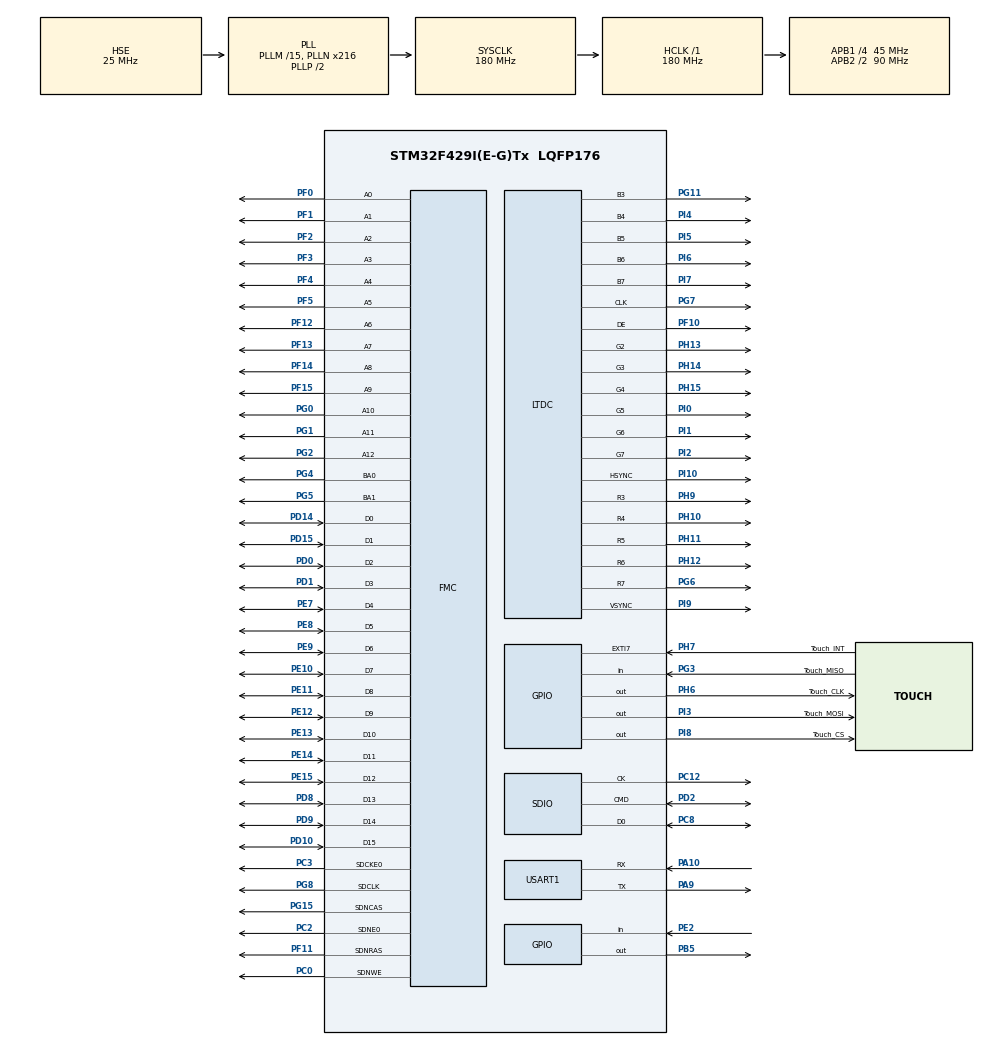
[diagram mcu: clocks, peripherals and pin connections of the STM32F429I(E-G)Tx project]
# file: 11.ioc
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DMA2D.ColorMode=DMA2D_OUTPUT_RGB565
FATFS.BSP.number=1
FATFS0.BSP.STBoard=false
FATFS0.BSP.api=Unknown
FATFS0.BSP.i2caddr=0
FATFS0.BSP.instance=PE2
FATFS0.BSP.ip=GPIO
FATFS0.BSP.mode=Input
FATFS0.BSP.name=Detect_SDIO
FATFS0.BSP.solution=PE2
FMC.CASLatency1=FMC_SDRAM_CAS_LATENCY_3
FMC.ColumnBitsNumber1=FMC_SDRAM_COLUMN_BITS_NUM_9
FMC.ExitSelfRefreshDelay1=7
FMC.LoadToActiveDelay1=2
FMC.RCDDelay1=2
FMC.RPDelay1=2
FMC.ReadBurst1=FMC_SDRAM_RBURST_ENABLE
FMC.RowCycleDelay1=6
FMC.SDClockPeriod1=FMC_SDRAM_CLOCK_PERIOD_2
FMC.SelfRefreshTime1=6
FMC.WriteRecoveryTime1=5
LTDC.ActiveW=800
LTDC.Alpha_L0=255
LTDC.Blue_L0=0
LTDC.HFP=210
LTDC.ImageHeight_L0=480
LTDC.ImageWidth_L0=800
LTDC.Layers=0
LTDC.PixelFormat_L0=LTDC_PIXEL_FORMAT_RGB565
LTDC.Red=0
LTDC.Red_L0=250
LTDC.VFP=22
LTDC.WindowX0_L0=0
LTDC.WindowX1_L0=800
LTDC.WindowY0_L0=0
LTDC.WindowY1_L0=480
Mcu.Family=STM32F4
Mcu.Name=STM32F429I(E-G)Tx
Mcu.Package=LQFP176
NVIC.DMA2D_IRQn=true\:0\:0\:false\:false\:true\:true\:true
NVIC.EXTI9_5_IRQn=true\:0\:0\:false\:false\:true\:true\:true
NVIC.LTDC_ER_IRQn=true\:0\:0\:false\:false\:true\:true\:true
NVIC.LTDC_IRQn=true\:0\:0\:false\:false\:true\:true\:true
NVIC.PriorityGroup=NVIC_PRIORITYGROUP_4
PA10.Mode=Asynchronous
PA10.Signal=USART1_RX
PA13.Mode=Serial_Wire
PA13.Signal=SYS_JTMS-SWDIO
PA14.Mode=Serial_Wire
PA14.Signal=SYS_JTCK-SWCLK
PA9.Mode=Asynchronous
PA9.Signal=USART1_TX
PB5.Signal=GPIO_Output
PC0.Signal=FMC_SDNWE
PC12.Mode=SD_1_bit
PC12.Signal=SDIO_CK
PC2.Mode=SdramChipSelect1_1
PC2.Signal=FMC_SDNE0
PC3.Mode=SdramChipSelect1_1
PC3.Signal=FMC_SDCKE0
PC8.Mode=SD_1_bit
PC8.Signal=SDIO_D0
PD0.Signal=FMC_D2_DA2
PD1.Signal=FMC_D3_DA3
PD10.Signal=FMC_D15_DA15
PD14.Signal=FMC_D0_DA0
PD15.Signal=FMC_D1_DA1
PD2.Mode=SD_1_bit
PD2.Signal=SDIO_CMD
PD8.Signal=FMC_D13_DA13
PD9.Signal=FMC_D14_DA14
PE10.Signal=FMC_D7_DA7
PE11.Signal=FMC_D8_DA8
PE12.Signal=FMC_D9_DA9
PE13.Signal=FMC_D10_DA10
PE14.Signal=FMC_D11_DA11
PE15.Signal=FMC_D12_DA12
PE2.Signal=GPIO_Input
PE7.Signal=FMC_D4_DA4
PE8.Signal=FMC_D5_DA5
PE9.Signal=FMC_D6_DA6
PF0.Signal=FMC_A0
PF1.Signal=FMC_A1
PF10.Mode=RGB565
PF10.Signal=LTDC_DE
PF11.Signal=FMC_SDNRAS
PF12.Signal=FMC_A6
PF13.Signal=FMC_A7
PF14.Signal=FMC_A8
PF15.Signal=FMC_A9
PF2.Signal=FMC_A2
PF3.Signal=FMC_A3
PF4.Signal=FMC_A4
PF5.Signal=FMC_A5
PG0.Signal=FMC_A10
PG1.Signal=FMC_A11
PG11.Mode=RGB565
PG11.Signal=LTDC_B3
PG15.Signal=FMC_SDNCAS
PG2.Signal=FMC_A12
PG3.GPIO_Label=Touch_MISO
PG3.Signal=GPIO_Input
PG4.Signal=FMC_A14_BA0
PG5.Signal=FMC_A15_BA1
PG6.Mode=RGB565
PG6.Signal=LTDC_R7
PG7.Mode=RGB565
PG7.Signal=LTDC_CLK
PG8.Signal=FMC_SDCLK
PH0/OSC_IN.Mode=HSE-External-Oscillator
PH0/OSC_IN.Signal=RCC_OSC_IN
PH1/OSC_OUT.Mode=HSE-External-Oscillator
PH1/OSC_OUT.Signal=RCC_OSC_OUT
PH10.Mode=RGB565
PH10.Signal=LTDC_R4
PH11.Mode=RGB565
PH11.Signal=LTDC_R5
PH12.Mode=RGB565
PH12.Signal=LTDC_R6
PH13.Mode=RGB565
PH13.Signal=LTDC_G2
PH14.Mode=RGB565
PH14.Signal=LTDC_G3
PH15.Mode=RGB565
PH15.Signal=LTDC_G4
PH6.GPIO_Label=Touch_CLK
PH6.Signal=GPIO_Output
PH7.GPIO_Label=Touch_INT
PH7.GPIO_ModeDefaultEXTI=GPIO_MODE_IT_FALLING
PH7.GPIO_PuPd=GPIO_PULLUP
PH7.Signal=GPXTI7
PH9.Mode=RGB565
PH9.Signal=LTDC_R3
PI0.Mode=RGB565
PI0.Signal=LTDC_G5
PI1.Mode=RGB565
PI1.Signal=LTDC_G6
PI10.Mode=RGB565
PI10.Signal=LTDC_HSYNC
PI2.Mode=RGB565
PI2.Signal=LTDC_G7
PI3.GPIO_Label=Touch_MOSI
PI3.Signal=GPIO_Output
PI4.Mode=RGB565
PI4.Signal=LTDC_B4
PI5.Mode=RGB565
PI5.Signal=LTDC_B5
PI6.Mode=RGB565
PI6.Signal=LTDC_B6
PI7.Mode=RGB565
PI7.Signal=LTDC_B7
PI8.GPIO_Label=Touch_CS
PI8.Signal=GPIO_Output
PI9.Mode=RGB565
PI9.Signal=LTDC_VSYNC
ProjectManager.HeapSize=0x2000
ProjectManager.StackSize=0x4000
ProjectManager.TargetToolchain=STM32CubeIDE
RCC.48MHZClocksFreq_Value=45000000
RCC.AHBFreq_Value=180000000
RCC.APB1CLKDivider=RCC_HCLK_DIV4
RCC.APB1Freq_Value=45000000
RCC.APB1TimFreq_Value=90000000
RCC.APB2CLKDivider=RCC_HCLK_DIV2
RCC.APB2Freq_Value=90000000
RCC.APB2TimFreq_Value=180000000
RCC.CortexFreq_Value=180000000
RCC.HCLKFreq_Value=180000000
RCC.HSE_VALUE=25000000
RCC.HSI_VALUE=16000000
RCC.LSE_VALUE=32768
RCC.PLLM=15
RCC.PLLN=216
RCC.PLLQ=8
RCC.PLLSAIN=60
RCC.PLLSourceVirtual=RCC_PLLSOURCE_HSE
RCC.SYSCLKFreq_VALUE=180000000
RCC.SYSCLKSource=RCC_SYSCLKSOURCE_PLLCLK
RCC.VCOOutputFreq_Value=360000000
SH.FMC_A0.0=FMC_A0,13b-sda1
SH.FMC_A1.0=FMC_A1,13b-sda1
SH.FMC_A10.0=FMC_A10,13b-sda1
SH.FMC_A11.0=FMC_A11,13b-sda1
SH.FMC_A12.0=FMC_A12,13b-sda1
SH.FMC_A14_BA0.0=FMC_BA0,FourSdramBanks1
SH.FMC_A15_BA1.0=FMC_BA1,FourSdramBanks1
SH.FMC_A2.0=FMC_A2,13b-sda1
SH.FMC_A3.0=FMC_A3,13b-sda1
SH.FMC_A4.0=FMC_A4,13b-sda1
SH.FMC_A5.0=FMC_A5,13b-sda1
SH.FMC_A6.0=FMC_A6,13b-sda1
SH.FMC_A7.0=FMC_A7,13b-sda1
SH.FMC_A8.0=FMC_A8,13b-sda1
SH.FMC_A9.0=FMC_A9,13b-sda1
SH.FMC_D0_DA0.0=FMC_D0,sd-16b-d1
SH.FMC_D10_DA10.0=FMC_D10,sd-16b-d1
SH.FMC_D11_DA11.0=FMC_D11,sd-16b-d1
SH.FMC_D12_DA12.0=FMC_D12,sd-16b-d1
SH.FMC_D13_DA13.0=FMC_D13,sd-16b-d1
SH.FMC_D14_DA14.0=FMC_D14,sd-16b-d1
SH.FMC_D15_DA15.0=FMC_D15,sd-16b-d1
SH.FMC_D1_DA1.0=FMC_D1,sd-16b-d1
SH.FMC_D2_DA2.0=FMC_D2,sd-16b-d1
SH.FMC_D3_DA3.0=FMC_D3,sd-16b-d1
SH.FMC_D4_DA4.0=FMC_D4,sd-16b-d1
SH.FMC_D5_DA5.0=FMC_D5,sd-16b-d1
SH.FMC_D6_DA6.0=FMC_D6,sd-16b-d1
SH.FMC_D7_DA7.0=FMC_D7,sd-16b-d1
SH.FMC_D8_DA8.0=FMC_D8,sd-16b-d1
SH.FMC_D9_DA9.0=FMC_D9,sd-16b-d1
SH.FMC_SDCLK.0=FMC_SDCLK,13b-sda1
SH.FMC_SDNCAS.0=FMC_SDNCAS,13b-sda1
SH.FMC_SDNRAS.0=FMC_SDNRAS,13b-sda1
SH.FMC_SDNWE.0=FMC_SDNWE,13b-sda1
STMicroelectronics.X-CUBE-TOUCHGFX.4.13.0.ApplicationCcGraphicsJjApplication=TouchGFXOoGenerator
STMicroelectronics.X-CUBE-TOUCHGFX.4.13.0.tgfx_address1=0XC0000000
STMicroelectronics.X-CUBE-TOUCHGFX.4.13.0.tgfx_buffering_strategy=Single
STMicroelectronics.X-CUBE-TOUCHGFX.4.13.0.tgfx_custom_height=480
STMicroelectronics.X-CUBE-TOUCHGFX.4.13.0.tgfx_display_interface=disp_ltdc
STMicroelectronics.X-CUBE-TOUCHGFX.4.13.0.tgfx_hardware_accelerator=dma_2d
STMicroelectronics.X-CUBE-TOUCHGFX.4.13.0.tgfx_location=By Address
STMicroelectronics.X-CUBE-TOUCHGFX.4.13.0.tgfx_ltdc_height=480
STMicroelectronics.X-CUBE-TOUCHGFX.4.13.0.tgfx_ltdc_width=800
STMicroelectronics.X-CUBE-TOUCHGFX.4.13.0.tgfx_vsync=vsync_ltdc
USART1.VirtualMode=VM_ASYNC
VP_CRC_VS_CRC.Mode=CRC_Activate
VP_DMA2D_VS_DMA2D.Mode=DMA2D_Activate
VP_FATFS_VS_SDIO.Mode=SDIO
VP_STMicroelectronics.X-CUBE-TOUCHGFX_VS_GraphicsJjApplication_4.13.0.Mode=GraphicsJjApplication
board=custom

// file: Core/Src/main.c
/* USER CODE BEGIN Header */
/**
  ******************************************************************************
  * @file           : main.c
  * @brief          : Main program body
  ******************************************************************************
  * @attention
  *
  * <h2><center>&copy; Copyright (c) 2020 STMicroelectronics.
  * All rights reserved.</center></h2>
  *
  * This software component is licensed by ST under BSD 3-Clause license,
  * the "License"; You may not use this file except in compliance with the
  * License. You may obtain a copy of the License at:
  *                        opensource.org/licenses/BSD-3-Clause
  *
  ******************************************************************************
  */
/* USER CODE END Header */

#include "main.h"
#include "crc.h"
#include "dma2d.h"
#include "fatfs.h"
#include "ltdc.h"
#include "sdio.h"
#include "usart.h"
#include "gpio.h"
#include "fmc.h"
#include "app_touchgfx.h"

/* USER CODE BEGIN Includes */
//#include "XPTC.h"
#include "stdbool.h"
bool data=false;
bool toggle;
/* USER CODE END Includes */

void SystemClock_Config(void);

int main(void)
{
  /* USER CODE BEGIN 1 */
	toggle = false;

  /* USER CODE END 1 */

  /* MCU Configuration--------------------------------------------------------*/

  /* Reset of all peripherals, Initializes the Flash interface and the Systick. */
  HAL_Init();

  /* Configure the system clock */
  SystemClock_Config();

  /* Initialize all configured peripherals */
  MX_GPIO_Init();
  MX_FMC_Init();
  FMC_SDRAM_CommandTypeDef command;
////Enable The clock
HAL_Delay(100);
command.CommandMode = FMC_SDRAM_CMD_CLK_ENABLE;
command.CommandTarget = FMC_SDRAM_CMD_TARGET_BANK1;
command.AutoRefreshNumber= 2;
command.ModeRegisterDefinition=0;
HAL_SDRAM_SendCommand(&hsdram1, &command, 5000);
HAL_Delay(100);
////Precharge SDRAM
command.CommandMode = FMC_SDRAM_CMD_PALL;
command.CommandTarget = FMC_SDRAM_CMD_TARGET_BANK1;
command.AutoRefreshNumber= 4;
command.ModeRegisterDefinition=0;
HAL_SDRAM_SendCommand(&hsdram1, &command, 5000);
HAL_Delay(100);
////Precharge SDRAM
command.CommandMode = FMC_SDRAM_CMD_AUTOREFRESH_MODE;
command.CommandTarget = FMC_SDRAM_CMD_TARGET_BANK1;
command.AutoRefreshNumber= 8;
command.ModeRegisterDefinition=0;
HAL_SDRAM_SendCommand(&hsdram1, &command, 5000);
HAL_Delay(100);
///
command.CommandMode = FMC_SDRAM_CMD_LOAD_MODE;
    command.CommandTarget = FMC_SDRAM_CMD_TARGET_BANK1;
    command.AutoRefreshNumber= 4;
    command.ModeRegisterDefinition=0x130;
    HAL_SDRAM_SendCommand(&hsdram1, &command, 5000);
    HAL_Delay(100);
    ///
HAL_SDRAM_WriteProtection_Disable(&hsdram1);
HAL_Delay(100);
  MX_USART1_UART_Init();
  MX_CRC_Init();
  MX_LTDC_Init();
  MX_SDIO_SD_Init();
  MX_FATFS_Init();
  MX_DMA2D_Init();
  MX_TouchGFX_Init();
  /* USER CODE BEGIN 2 */
  /*
	////////////////////////////////////////////////////////////////////////////SDRAM CONFIG
	   FMC_SDRAM_CommandTypeDef command;
     ////Enable The clock
     HAL_Delay(100);
     command.CommandMode = FMC_SDRAM_CMD_CLK_ENABLE;
     command.CommandTarget = FMC_SDRAM_CMD_TARGET_BANK1;
     command.AutoRefreshNumber= 2;
     command.ModeRegisterDefinition=0;
     HAL_SDRAM_SendCommand(&hsdram1, &command, 5000);
     HAL_Delay(100);
     ////Precharge SDRAM
     command.CommandMode = FMC_SDRAM_CMD_PALL;
     command.CommandTarget = FMC_SDRAM_CMD_TARGET_BANK1;
     command.AutoRefreshNumber= 4;
     command.ModeRegisterDefinition=0;
     HAL_SDRAM_SendCommand(&hsdram1, &command, 5000);
     HAL_Delay(100);
     ////Precharge SDRAM
     command.CommandMode = FMC_SDRAM_CMD_AUTOREFRESH_MODE;
     command.CommandTarget = FMC_SDRAM_CMD_TARGET_BANK1;
     command.AutoRefreshNumber= 8;
     command.ModeRegisterDefinition=0;
     HAL_SDRAM_SendCommand(&hsdram1, &command, 5000);
     HAL_Delay(100);
     ///
     command.CommandMode = FMC_SDRAM_CMD_LOAD_MODE;
         command.CommandTarget = FMC_SDRAM_CMD_TARGET_BANK1;
         command.AutoRefreshNumber= 4;
         command.ModeRegisterDefinition=0x130;
         HAL_SDRAM_SendCommand(&hsdram1, &command, 5000);
         HAL_Delay(100);
         ///
     HAL_SDRAM_WriteProtection_Disable(&hsdram1);
     HAL_Delay(100);
	 */
     ///////////////////////////////////////////////////////////////////////////TURN LCD ON
       HAL_GPIO_WritePin(GPIOB, GPIO_PIN_5, GPIO_PIN_SET);
        HAL_UART_Transmit(&huart1, (uint8_t*)"START\n", 6, 5000);
        //XPT_init();
       ///////////////////////////////////////////////////////////////
  /* USER CODE END 2 */

  /* Infinite loop */
  /* USER CODE BEGIN WHILE */
        FIL pngfile;
        //char pngpath[]="\pic.png\0";
        char pngbuffer[6000];
        UINT pngcounter;

  while (1)
  {

  MX_TouchGFX_Process();
  }
}

void SystemClock_Config(void)
{
  RCC_OscInitTypeDef RCC_OscInitStruct = {0};
  RCC_ClkInitTypeDef RCC_ClkInitStruct = {0};
  RCC_PeriphCLKInitTypeDef PeriphClkInitStruct = {0};

  /** Configure the main internal regulator output voltage
  */
  __HAL_RCC_PWR_CLK_ENABLE();
  __HAL_PWR_VOLTAGESCALING_CONFIG(PWR_REGULATOR_VOLTAGE_SCALE1);
  /** Initializes the CPU, AHB and APB busses clocks
  */
  RCC_OscInitStruct.OscillatorType = RCC_OSCILLATORTYPE_HSE;
  RCC_OscInitStruct.HSEState = RCC_HSE_ON;
  RCC_OscInitStruct.PLL.PLLState = RCC_PLL_ON;
  RCC_OscInitStruct.PLL.PLLSource = RCC_PLLSOURCE_HSE;
  RCC_OscInitStruct.PLL.PLLM = 15;
  RCC_OscInitStruct.PLL.PLLN = 216;
  RCC_OscInitStruct.PLL.PLLP = RCC_PLLP_DIV2;
  RCC_OscInitStruct.PLL.PLLQ = 8;
  if (HAL_RCC_OscConfig(&RCC_OscInitStruct) != HAL_OK)
  {
    Error_Handler();
  }
  /** Activate the Over-Drive mode
  */
  if (HAL_PWREx_EnableOverDrive() != HAL_OK)
  {
    Error_Handler();
  }
  /** Initializes the CPU, AHB and APB busses clocks
  */
  RCC_ClkInitStruct.ClockType = RCC_CLOCKTYPE_HCLK|RCC_CLOCKTYPE_SYSCLK
                              |RCC_CLOCKTYPE_PCLK1|RCC_CLOCKTYPE_PCLK2;
  RCC_ClkInitStruct.SYSCLKSource = RCC_SYSCLKSOURCE_PLLCLK;
  RCC_ClkInitStruct.AHBCLKDivider = RCC_SYSCLK_DIV1;
  RCC_ClkInitStruct.APB1CLKDivider = RCC_HCLK_DIV4;
  RCC_ClkInitStruct.APB2CLKDivider = RCC_HCLK_DIV2;

  if (HAL_RCC_ClockConfig(&RCC_ClkInitStruct, FLASH_LATENCY_5) != HAL_OK)
  {
    Error_Handler();
  }
  PeriphClkInitStruct.PeriphClockSelection = RCC_PERIPHCLK_LTDC;
  PeriphClkInitStruct.PLLSAI.PLLSAIN = 60;
  PeriphClkInitStruct.PLLSAI.PLLSAIR = 2;
  PeriphClkInitStruct.PLLSAIDivR = RCC_PLLSAIDIVR_2;
  if (HAL_RCCEx_PeriphCLKConfig(&PeriphClkInitStruct) != HAL_OK)
  {
    Error_Handler();
  }
}

/* USER CODE BEGIN 4 */

////////////////////////////////

/* USER CODE END 4 */

void Error_Handler(void)
{
}

/************************ (C) COPYRIGHT STMicroelectronics *****END OF FILE****/
